# apollo3 register map
Vendor: Ambiq Micro; Series: Apollo; File version: 1.0
CPU: CM4 r1p0, little endian, MPU, FPU, 3 interrupt priority bits
Registers are 32-bit, read-write, reset 0x0 unless marked. A register's access mark holds for its fields unless they carry their own. Offsets are from the block's base; [hi:lo] are bit positions; {n}, {i} and the like mark numbered series; 'fields as' and 'values as' point back to an identical list.

## PDM — PDM Audio
Base 0x50011000
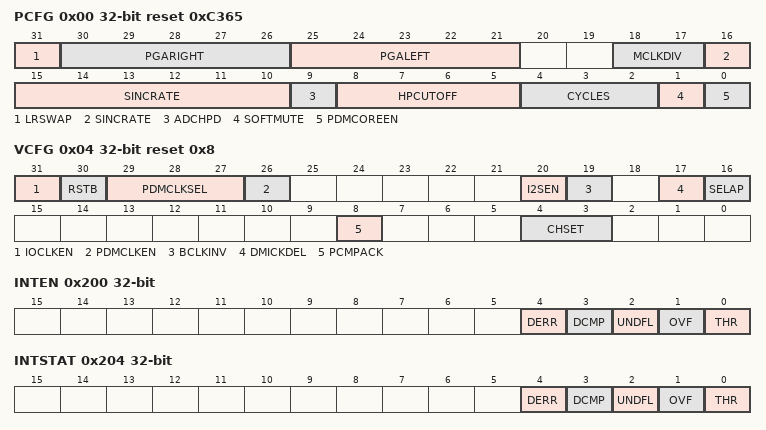
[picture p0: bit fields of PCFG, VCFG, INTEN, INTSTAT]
0x00 PCFG reset 0xC365 — PDM Configuration Register
  [31] LRSWAP — Left/right channel swap.
    1=EN (Swap left and right channels (FIFO Read RIGHT_LEFT).); 0=NOSWAP (No channel swapping (IFO Read LEFT_RIGHT).)
  [30:26] PGARIGHT — Right channel PGA gain.
    31=P405DB (40.5 db gain.); 30=P390DB (39.0 db gain.); 29=P375DB (37.5 db gain.); 28=P360DB (36.0 db gain.); 27=P345DB (34.5 db gain.); 26=P330DB (33.0 db gain.); 25=P315DB (31.5 db gain.); 24=P300DB (30.0 db gain.); 23=P285DB (28.5 db gain.); 22=P270DB (27.0 db gain.); 21=P255DB (25.5 db gain.); 20=P240DB (24.0 db gain.); 19=P225DB (22.5 db gain.); 18=P210DB (21.0 db gain.); 17=P195DB (19.5 db gain.); 16=P180DB (18.0 db gain.); 15=P165DB (16.5 db gain.); 14=P150DB (15.0 db gain.); 13=P135DB (13.5 db gain.); 12=P120DB (12.0 db gain.); 11=P105DB (10.5 db gain.); 10=P90DB (9.0 db gain.); 9=P75DB (7.5 db gain.); 8=P60DB (6.0 db gain.); 7=P45DB (4.5 db gain.); 6=P30DB (3.0 db gain.); 5=P15DB (1.5 db gain.); 4=0DB (0.0 db gain.); 3=M15DB (-1.5 db gain.); 2=M300DB (-3.0 db gain.); 1=M45DB (-4.5 db gain.); 0=M60DB (-6.0 db gain.)
  [25:21] PGALEFT — Left channel PGA gain.
    values as PGARIGHT
  [18:17] MCLKDIV — PDM_CLK frequency divisor.
    {v}=MCKDIV{v+1} (Divide input clock by {v+1}) (v=0..3)
  [16:10] SINCRATE — SINC decimation rate.
  [9] ADCHPD — High pass filter control.
    0=EN (Enable high pass filter.); 1=DIS (Disable high pass filter.)
  [8:5] HPCUTOFF — High pass filter coefficients.
  [4:2] CYCLES — Number of clocks during gain-setting changes.
  [1] SOFTMUTE — Soft mute control.
    1=EN (Enable Soft Mute.); 0=DIS (Disable Soft Mute.)
  [0] PDMCOREEN — Data Streaming Control.
    1=EN (Enable Data Streaming.); 0=DIS (Disable Data Streaming.)
0x04 VCFG reset 0x8 — Voice Configuration Register
  [31] IOCLKEN — Enable the IO clock.
    0=DIS (Disable FIFO read.); 1=EN (Enable FIFO read.)
  [30] RSTB — Reset the IP core.
    0=RESET (Reset the core.); 1=NORM (Enable the core.)
  [29:27] PDMCLKSEL — Select the PDM input clock.
    0=DISABLE (Static value.); 1=12MHz (PDM clock is 12 MHz.); 2=6MHz (PDM clock is 6 MHz.); 3=3MHz (PDM clock is 3 MHz.); 4=1_5MHz (PDM clock is 1.5 MHz.); 5=750KHz (PDM clock is 750 KHz.); 6=375KHz (PDM clock is 375 KHz.); 7=187KHz (PDM clock is 187.5 KHz.)
  [26] PDMCLKEN — Enable the serial clock.
    0=DIS (Disable serial clock.); 1=EN (Enable serial clock.)
  [20] I2SEN — I2S interface enable.
    0=DIS (Disable I2S interface.); 1=EN (Enable I2S interface.)
  [19] BCLKINV — I2S BCLK input inversion.
    0=INV (BCLK inverted.); 1=NORM (BCLK not inverted.)
  [17] DMICKDEL — PDM clock sampling delay.
    0=0CYC (No delay.); 1=1CYC (1 cycle delay.)
  [16] SELAP — Select PDM input clock source.
    1=I2S (Clock source from I2S BCLK.); 0=INTERNAL (Clock source from internal clock generator.)
  [8] PCMPACK — PCM data packing enable.
    0=DIS (Disable PCM packing.); 1=EN (Enable PCM packing.)
  [4:3] CHSET — Set PCM channels.
    0=DIS (Channel disabled.); 1=LEFT (Mono left channel.); 2=RIGHT (Mono right channel.); 3=STEREO (Stereo channels.)
0x08 VOICESTAT — Voice Status Register
  [5:0] FIFOCNT — Valid 32-bit entries currently in the FIFO.
0x0C FIFOREAD
  [31:0] FIFOREAD — FIFO read data.
0x10 FIFOFLUSH
  [0] FIFOFLUSH
0x14 FIFOTHR reset 0x10 — FIFO Threshold
  [4:0] FIFOTHR — FIFO Threshold value. When the FIFO count is equal to, or larger than this value (in words), a THR interrupt is generated (if enabled)
0x200 INTEN — Set bits in this register to allow this module to generate the corresponding interrupt.
  [4] DERR — DMA Error receieved
  [3] DCMP — DMA completed a transfer
  [2] UNDFL — This is the FIFO underflow interrupt.
  [1] OVF — This is the FIFO overflow interrupt.
  [0] THR — This is the FIFO threshold interrupt.
0x204 INTSTAT — Read bits from this register to discover the cause of a recent interrupt.
  fields as INTEN
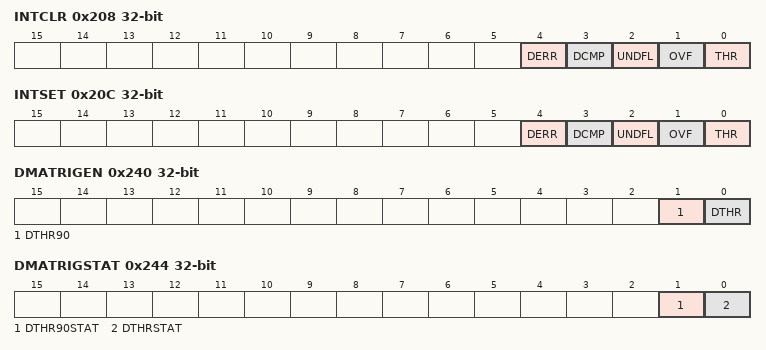
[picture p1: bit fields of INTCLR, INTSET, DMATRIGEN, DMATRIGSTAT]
0x208 INTCLR — Write a 1 to a bit in this register to clear the interrupt status associated with that bit.
  fields as INTEN
0x20C INTSET — Write a 1 to a bit in this register to instantly generate an interrupt from this module. (Generally used for testing purposes).
  fields as INTEN
0x240 DMATRIGEN — DMA Trigger Enable Register
  [1] DTHR90 — Trigger DMA at FIFO 90 percent full. This signal is also used internally for AUTOHIP function
  [0] DTHR — Trigger DMA upon when FIFO iss filled to level indicated by the FIFO THRESHOLD,at granularity of 16 bytes only
0x244 DMATRIGSTAT — DMA Trigger Status Register
  [1] DTHR90STAT — Triggered DMA from FIFO reaching 90 percent full
  [0] DTHRSTAT — Triggered DMA from FIFO reaching threshold
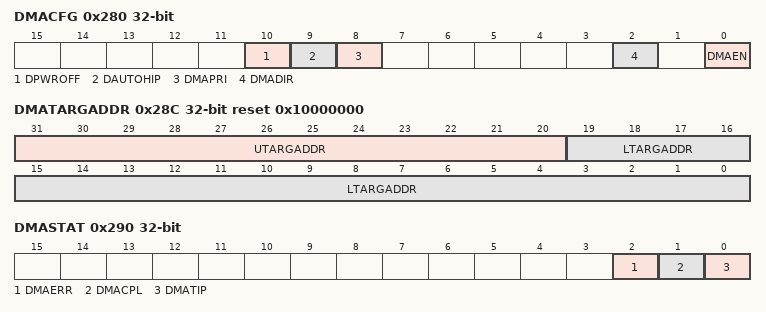
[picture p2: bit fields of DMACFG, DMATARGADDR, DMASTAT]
0x280 DMACFG — DMA Configuration Register
  [10] DPWROFF — Power Off the ADC System upon DMACPL.
  [9] DAUTOHIP — Raise priority to high on fifo full, and DMAPRI set to low
  [8] DMAPRI — Sets the Priority of the DMA request
    0=LOW (Low Priority (service as best effort)); 1=HIGH (High Priority (service immediately))
  [2] DMADIR — Direction
    0=P2M (Peripheral to Memory (SRAM) transaction. THe PDM module will only DMA to memory.); 1=M2P (Memory to Peripheral transaction. Not available for PDM module)
  [0] DMAEN — DMA Enable
    0=DIS (Disable DMA Function); 1=EN (Enable DMA Function)
0x288 DMATOTCOUNT — DMA Total Transfer Count
  [19:0] TOTCOUNT — Total Transfer Count. The transfer count must be a multiple of the THR setting to avoid DMA overruns.
0x28C DMATARGADDR reset 0x10000000 — DMA Target Address Register
  [31:20] UTARGADDR — SRAM Target
  [19:0] LTARGADDR — DMA Target Address. This register is not updated with the current address of the DMA, but will remain static with the original address during the DMA transfer.
0x290 DMASTAT — DMA Status Register
  [2] DMAERR — DMA Error
  [1] DMACPL — DMA Transfer Complete
  [0] DMATIP — DMA Transfer In Progress
